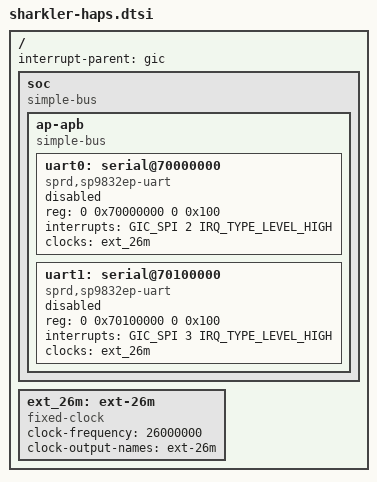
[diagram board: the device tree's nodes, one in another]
// SPDX-License-Identifier: (GPL-2.0+ OR MIT)
/*
 * Unisoc Sharkler platform DTS file
 *
 * Copyright (C) 2018, Unisoc Communications Inc.
 */

#include <dt-bindings/interrupt-controller/arm-gic.h>

/ {
	interrupt-parent = <&gic>;
	#address-cells = <2>;
	#size-cells = <2>;

	soc: soc {
		compatible = "simple-bus";
		#address-cells = <2>;
		#size-cells = <2>;
		ranges;

		ap-apb {
			compatible = "simple-bus";
			#address-cells = <2>;
			#size-cells = <2>;
			ranges;

			uart0: serial@70000000 {
				compatible = "sprd,sp9832ep-uart",
					     "sprd,sc9836-uart";
				reg = <0 0x70000000 0 0x100>;
				interrupts = <GIC_SPI 2 IRQ_TYPE_LEVEL_HIGH>;
				clock-names = "enable", "uart", "source";
				clocks = <&ext_26m>;
				status = "disabled";
			};

			uart1: serial@70100000 {
				compatible = "sprd,sp9832ep-uart",
					     "sprd,sc9836-uart";
				reg = <0 0x70100000 0 0x100>;
				interrupts = <GIC_SPI 3 IRQ_TYPE_LEVEL_HIGH>;
				clock-names = "enable", "uart", "source";
				clocks = <&ext_26m>;
				status = "disabled";
			};
		};
	};

	ext_26m: ext-26m {
		compatible = "fixed-clock";
		#clock-cells = <0>;
		clock-frequency = <26000000>;
		clock-output-names = "ext-26m";
	};
};
